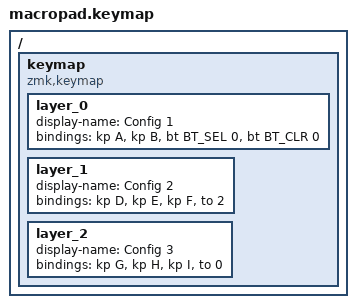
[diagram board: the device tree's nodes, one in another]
#include <behaviors.dtsi>
#include <dt-bindings/zmk/keys.h>
#include <dt-bindings/zmk/bt.h>

/ {
    keymap {
        compatible = "zmk,keymap";

        layer_0 {
            display-name = "Config 1";
            bindings = <
                &kp A     &kp B     &bt BT_SEL 0     &bt BT_CLR 0
            >;
        };

        layer_1 {
            display-name = "Config 2";
            bindings = <
                &kp D     &kp E     &kp F     &to 2
            >;
        };

        layer_2 {
            display-name = "Config 3";
            bindings = <
                &kp G     &kp H     &kp I     &to 0
            >;
        };
    };
};
